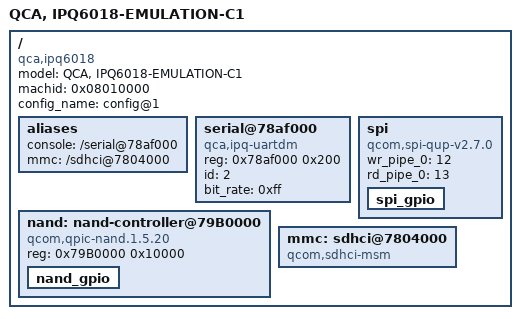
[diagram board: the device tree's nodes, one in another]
/*
 * Copyright (c) 2016-2018, The Linux Foundation. All rights reserved.
 *
 * This program is free software; you can redistribute it and/or modify
 * it under the terms of the GNU General Public License version 2 and
 * only version 2 as published by the Free Software Foundation.
 *
 * This program is distributed in the hope that it will be useful,
 * but WITHOUT ANY WARRANTY; without even the implied warranty of
 * MERCHANTABILITY or FITNESS FOR A PARTICULAR PURPOSE.  See the
 * GNU General Public License for more details.
 */

/dts-v1/;
#include "ipq6018-soc.dtsi"
/ {
	model ="QCA, IPQ6018-EMULATION-C1";
	compatible = "qca,ipq6018", "qca,ipq6018-emulation-c1";
	machid = <0x08010000>;
	config_name = "config@1";

	aliases {
		console = "/serial@78af000";
		mmc = "/sdhci@7804000";
	};
	serial@78af000 {
		compatible = "qca,ipq-uartdm";
		reg = <0x78af000 0x200>;
		id = <2>;
		bit_rate = <0xff>;
		status = "ok";
	};
	spi {
		compatible = "qcom,spi-qup-v2.7.0";
		wr_pipe_0 = <12>;
		rd_pipe_0 = <13>;
		status = "ok";
		spi_gpio {};
	};
	nand: nand-controller@79B0000 {
		compatible = "qcom,qpic-nand.1.5.20";
		reg = <0x79B0000 0x10000>;
		status = "ok";
		nand_gpio {};
	};

	mmc: sdhci@7804000 {
		compatible = "qcom,sdhci-msm";
        };

};
